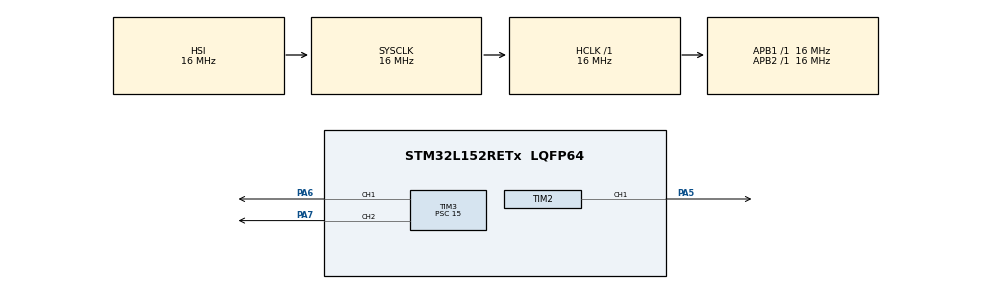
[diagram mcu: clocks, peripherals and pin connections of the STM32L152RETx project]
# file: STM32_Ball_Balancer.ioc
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Mcu.Family=STM32L1
Mcu.Name=STM32L152RETx
Mcu.Package=LQFP64
NVIC.PriorityGroup=NVIC_PRIORITYGROUP_4
PA5.Signal=S_TIM2_CH1_ETR
PA6.Signal=S_TIM3_CH1
PA7.Signal=S_TIM3_CH2
ProjectManager.HeapSize=0x200
ProjectManager.StackSize=0x400
ProjectManager.TargetToolchain=STM32CubeIDE
RCC.AHBFreq_Value=16000000
RCC.APB1Freq_Value=16000000
RCC.APB1TimFreq_Value=16000000
RCC.APB2Freq_Value=16000000
RCC.APB2TimFreq_Value=16000000
RCC.HCLKFreq_Value=16000000
RCC.HSE_VALUE=24000000
RCC.HSI_VALUE=16000000
RCC.LSE_VALUE=32768
RCC.MSI_VALUE=2097000
RCC.SYSCLKFreq_VALUE=16000000
RCC.SYSCLKSource=RCC_SYSCLKSOURCE_HSI
RCC.VCOOutputFreq_Value=48000000
SH.S_TIM2_CH1_ETR.0=TIM2_CH1,PWM Generation1 CH1
SH.S_TIM3_CH1.0=TIM3_CH1,PWM Generation1 CH1
SH.S_TIM3_CH2.0=TIM3_CH2,PWM Generation2 CH2
TIM2.AutoReloadPreload=TIM_AUTORELOAD_PRELOAD_ENABLE
TIM2.Channel-PWM\ Generation1\ CH1=TIM_CHANNEL_1
TIM2.Period=19999
TIM2.Prescaler=15
TIM2.Pulse-PWM\ Generation1\ CH1=1500
TIM3.AutoReloadPreload=TIM_AUTORELOAD_PRELOAD_ENABLE
TIM3.Channel-PWM\ Generation1\ CH1=TIM_CHANNEL_1
TIM3.Channel-PWM\ Generation2\ CH2=TIM_CHANNEL_2
TIM3.Period=19999
TIM3.Prescaler=15
TIM3.Pulse-PWM\ Generation1\ CH1=1500
TIM3.Pulse-PWM\ Generation2\ CH2=1500
VP_TIM2_VS_ClockSourceINT.Mode=Internal
VP_TIM3_VS_ClockSourceINT.Mode=Internal
board=custom

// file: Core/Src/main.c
/* USER CODE BEGIN Header */
/**
  ******************************************************************************
  * @file           : main.c
  * @brief          : Main program body
  ******************************************************************************
  * @attention
  *
  * Copyright (c) 2026 STMicroelectronics.
  * All rights reserved.
  *
  * This software is licensed under terms that can be found in the LICENSE file
  * in the root directory of this software component.
  * If no LICENSE file comes with this software, it is provided AS-IS.
  *
  ******************************************************************************
  */
/* USER CODE END Header */
#include "main.h"

TIM_HandleTypeDef htim2;
TIM_HandleTypeDef htim3;

/* USER CODE BEGIN PV */
static const int min_pixels = 80;
static const int max_misses = 3;
static int ball_x = 160;
static int ball_y = 120;
static int ball_count = 0;
static int miss_count = 0;
/* USER CODE END PV */

void SystemClock_Config(void);
static void MX_GPIO_Init(void);
static void MX_TIM2_Init(void);
static void MX_TIM3_Init(void);
/* USER CODE BEGIN PFP */
static void servos_set_deg(uint8_t a, uint8_t b, uint8_t c);
static void servos_startup(void);
static void uart_cam_init(void);
static void uart_poll(void);
/* USER CODE END PFP */

/* USER CODE BEGIN 0 */

static uint16_t deg_to_us(uint8_t degrees)
{
  if (degrees > 180) {
    degrees = 180;
  }
  return (uint16_t)(500 + ((uint32_t)degrees * 2000) / 180);
}

static void servos_set_deg(uint8_t a, uint8_t b, uint8_t c)
{
  __HAL_TIM_SET_COMPARE(&htim2, TIM_CHANNEL_1, deg_to_us(a)); /* PA5, D13 */
  __HAL_TIM_SET_COMPARE(&htim3, TIM_CHANNEL_1, deg_to_us(b)); /* PA6, D12 */
  __HAL_TIM_SET_COMPARE(&htim3, TIM_CHANNEL_2, deg_to_us(c)); /* PA7, D11 */
}

static void servos_startup(void) {
	servos_set_deg(120, 120, 120);
	HAL_Delay(800);
	servos_set_deg(60, 60, 60);
	HAL_Delay(800);
	servos_set_deg(100,100,100);
}

/* ESP32 GPIO1 TX -> PA10 D2 USART1 RX. */
static void uart_cam_init(void)
{
  GPIO_InitTypeDef gpio = {0};

  __HAL_RCC_GPIOA_CLK_ENABLE();
  __HAL_RCC_USART1_CLK_ENABLE();
  __HAL_RCC_USART2_CLK_ENABLE();

  gpio.Mode = GPIO_MODE_AF_PP;
  gpio.Pull = GPIO_PULLUP;
  gpio.Speed = GPIO_SPEED_FREQ_HIGH;
  gpio.Alternate = GPIO_AF7_USART1;
  gpio.Pin = GPIO_PIN_10;
  HAL_GPIO_Init(GPIOA, &gpio);

  gpio.Alternate = GPIO_AF7_USART2;
  gpio.Pin = GPIO_PIN_2;
  HAL_GPIO_Init(GPIOA, &gpio);

  /* 16 MHz clock, 115200 baud, oversampling 16. */
  USART1->CR1 = 0;
  USART1->BRR = 139;
  USART1->CR1 = USART_CR1_UE | USART_CR1_RE;

  USART2->CR1 = 0;
  USART2->BRR = 139;
  USART2->CR1 = USART_CR1_UE | USART_CR1_TE;
}

// send character to UART
static void uart_tx(char c)
{
  while ((USART2->SR & USART_SR_TXE) == 0) {
  }
  USART2->DR = (uint8_t)c;
}

// write integer to UART
static void uart_write_int(int value)
{
  char digits[8];
  int count = 0;

  if (value < 0) {
    uart_tx('-');
    value = -value;
  }
  if (value == 0) {
    uart_tx('0');
    return;
  }
  while (value > 0 && count < 8) {
    digits[count++] = (char)('0' + (value % 10));
    value /= 10;
  }
  while (count > 0) {
    uart_tx(digits[--count]);
  }
}

// format the sample from UART
static int read_sample(const char *text, int *x, int *y, int *count)
{
  int value = 0;
  int field = 0;

  while (*text != '\0') {
    if (*text == ' ') {
      if (field == 0) {
        *x = value;
      } else if (field == 1) {
        *y = value;
      }
      if (field < 2) {
        field++;
        value = 0;
      }
    } else if (*text >= '0' && *text <= '9') {
      value = value * 10 + (*text - '0');
    }
    text++;
  }
  if (field != 2) {
    return 0;
  }
  *count = value;
  return 1;
}

static void uart_poll(void)
{
  static char line[24];
  static int length = 0;

  while ((USART1->SR & USART_SR_RXNE) != 0) {
    char c = (char)(USART1->DR & 0xFF);
    if (c == '\n' || c == '\r') {
      if (length > 0) {
        int x = 0;
        int y = 0;
        int count = 0;
        line[length] = '\0';
        if (read_sample(line, &x, &y, &count)) {
          ball_count = count;
          if (ball_count >= min_pixels) { // filter out noise
            ball_x = x;
            ball_y = y;
            miss_count = 0;
          } else {
            miss_count++;
            if (miss_count >= max_misses) {
              ball_x = 160;
              ball_y = 120;
              miss_count = 0;
            }
          }
          uart_write_int(ball_x);
          uart_tx(' ');
          uart_write_int(ball_y);
          uart_tx(' ');
          uart_write_int(ball_count);
          uart_tx('\r');
          uart_tx('\n');
        }
        length = 0;
      }
    } else if (length < (int)sizeof(line) - 1) {
      line[length++] = c;
    }
  }
}
/* USER CODE END 0 */

int main(void)
{

  /* MCU Configuration--------------------------------------------------------*/

  /* Reset of all peripherals, Initializes the Flash interface and the Systick. */
  HAL_Init();

  /* Configure the system clock */
  SystemClock_Config();

  /* Initialize all configured peripherals */
  MX_GPIO_Init();
  MX_TIM2_Init();
  MX_TIM3_Init();
  /* USER CODE BEGIN 2 */
  HAL_TIM_PWM_Start(&htim2, TIM_CHANNEL_1); /* PA5, D13 */
  HAL_TIM_PWM_Start(&htim3, TIM_CHANNEL_1); /* PA6, D12 */
  HAL_TIM_PWM_Start(&htim3, TIM_CHANNEL_2); /* PA7, D11 */

  servos_startup();
  uart_cam_init();
   /* USER CODE END 2 */

  /* Infinite loop */
  while (1)
  {

    /* USER CODE BEGIN 3 */
    uart_poll();
  }
  /* USER CODE END 3 */
}

void SystemClock_Config(void)
{
  RCC_OscInitTypeDef RCC_OscInitStruct = {0};
  RCC_ClkInitTypeDef RCC_ClkInitStruct = {0};

  /** Configure the main internal regulator output voltage
  */
  __HAL_PWR_VOLTAGESCALING_CONFIG(PWR_REGULATOR_VOLTAGE_SCALE1);

  /** Initializes the RCC Oscillators according to the specified parameters
  * in the RCC_OscInitTypeDef structure.
  */
  RCC_OscInitStruct.OscillatorType = RCC_OSCILLATORTYPE_HSI;
  RCC_OscInitStruct.HSIState = RCC_HSI_ON;
  RCC_OscInitStruct.HSICalibrationValue = RCC_HSICALIBRATION_DEFAULT;
  RCC_OscInitStruct.PLL.PLLState = RCC_PLL_NONE;
  if (HAL_RCC_OscConfig(&RCC_OscInitStruct) != HAL_OK)
  {
    Error_Handler();
  }

  /** Initializes the CPU, AHB and APB buses clocks
  */
  RCC_ClkInitStruct.ClockType = RCC_CLOCKTYPE_HCLK|RCC_CLOCKTYPE_SYSCLK
                              |RCC_CLOCKTYPE_PCLK1|RCC_CLOCKTYPE_PCLK2;
  RCC_ClkInitStruct.SYSCLKSource = RCC_SYSCLKSOURCE_HSI;
  RCC_ClkInitStruct.AHBCLKDivider = RCC_SYSCLK_DIV1;
  RCC_ClkInitStruct.APB1CLKDivider = RCC_HCLK_DIV1;
  RCC_ClkInitStruct.APB2CLKDivider = RCC_HCLK_DIV1;

  if (HAL_RCC_ClockConfig(&RCC_ClkInitStruct, FLASH_LATENCY_0) != HAL_OK)
  {
    Error_Handler();
  }
}

static void MX_TIM2_Init(void)
{

  TIM_ClockConfigTypeDef sClockSourceConfig = {0};
  TIM_MasterConfigTypeDef sMasterConfig = {0};
  TIM_OC_InitTypeDef sConfigOC = {0};

  htim2.Instance = TIM2;
  htim2.Init.Prescaler = 15;
  htim2.Init.CounterMode = TIM_COUNTERMODE_UP;
  htim2.Init.Period = 19999;
  htim2.Init.ClockDivision = TIM_CLOCKDIVISION_DIV1;
  htim2.Init.AutoReloadPreload = TIM_AUTORELOAD_PRELOAD_ENABLE;
  if (HAL_TIM_Base_Init(&htim2) != HAL_OK)
  {
    Error_Handler();
  }
  sClockSourceConfig.ClockSource = TIM_CLOCKSOURCE_INTERNAL;
  if (HAL_TIM_ConfigClockSource(&htim2, &sClockSourceConfig) != HAL_OK)
  {
    Error_Handler();
  }
  if (HAL_TIM_PWM_Init(&htim2) != HAL_OK)
  {
    Error_Handler();
  }
  sMasterConfig.MasterOutputTrigger = TIM_TRGO_RESET;
  sMasterConfig.MasterSlaveMode = TIM_MASTERSLAVEMODE_DISABLE;
  if (HAL_TIMEx_MasterConfigSynchronization(&htim2, &sMasterConfig) != HAL_OK)
  {
    Error_Handler();
  }
  sConfigOC.OCMode = TIM_OCMODE_PWM1;
  sConfigOC.Pulse = 1500;
  sConfigOC.OCPolarity = TIM_OCPOLARITY_HIGH;
  sConfigOC.OCFastMode = TIM_OCFAST_DISABLE;
  if (HAL_TIM_PWM_ConfigChannel(&htim2, &sConfigOC, TIM_CHANNEL_1) != HAL_OK)
  {
    Error_Handler();
  }
  HAL_TIM_MspPostInit(&htim2);

}

static void MX_TIM3_Init(void)
{

  TIM_ClockConfigTypeDef sClockSourceConfig = {0};
  TIM_MasterConfigTypeDef sMasterConfig = {0};
  TIM_OC_InitTypeDef sConfigOC = {0};

  htim3.Instance = TIM3;
  htim3.Init.Prescaler = 15;
  htim3.Init.CounterMode = TIM_COUNTERMODE_UP;
  htim3.Init.Period = 19999;
  htim3.Init.ClockDivision = TIM_CLOCKDIVISION_DIV1;
  htim3.Init.AutoReloadPreload = TIM_AUTORELOAD_PRELOAD_ENABLE;
  if (HAL_TIM_Base_Init(&htim3) != HAL_OK)
  {
    Error_Handler();
  }
  sClockSourceConfig.ClockSource = TIM_CLOCKSOURCE_INTERNAL;
  if (HAL_TIM_ConfigClockSource(&htim3, &sClockSourceConfig) != HAL_OK)
  {
    Error_Handler();
  }
  if (HAL_TIM_PWM_Init(&htim3) != HAL_OK)
  {
    Error_Handler();
  }
  sMasterConfig.MasterOutputTrigger = TIM_TRGO_RESET;
  sMasterConfig.MasterSlaveMode = TIM_MASTERSLAVEMODE_DISABLE;
  if (HAL_TIMEx_MasterConfigSynchronization(&htim3, &sMasterConfig) != HAL_OK)
  {
    Error_Handler();
  }
  sConfigOC.OCMode = TIM_OCMODE_PWM1;
  sConfigOC.Pulse = 1500;
  sConfigOC.OCPolarity = TIM_OCPOLARITY_HIGH;
  sConfigOC.OCFastMode = TIM_OCFAST_DISABLE;
  if (HAL_TIM_PWM_ConfigChannel(&htim3, &sConfigOC, TIM_CHANNEL_1) != HAL_OK)
  {
    Error_Handler();
  }
  if (HAL_TIM_PWM_ConfigChannel(&htim3, &sConfigOC, TIM_CHANNEL_2) != HAL_OK)
  {
    Error_Handler();
  }
  HAL_TIM_MspPostInit(&htim3);

}

static void MX_GPIO_Init(void)
{

  /* GPIO Ports Clock Enable */
  __HAL_RCC_GPIOA_CLK_ENABLE();

}

void Error_Handler(void)
{
  __disable_irq();
  while (1)
  {
  }
}
